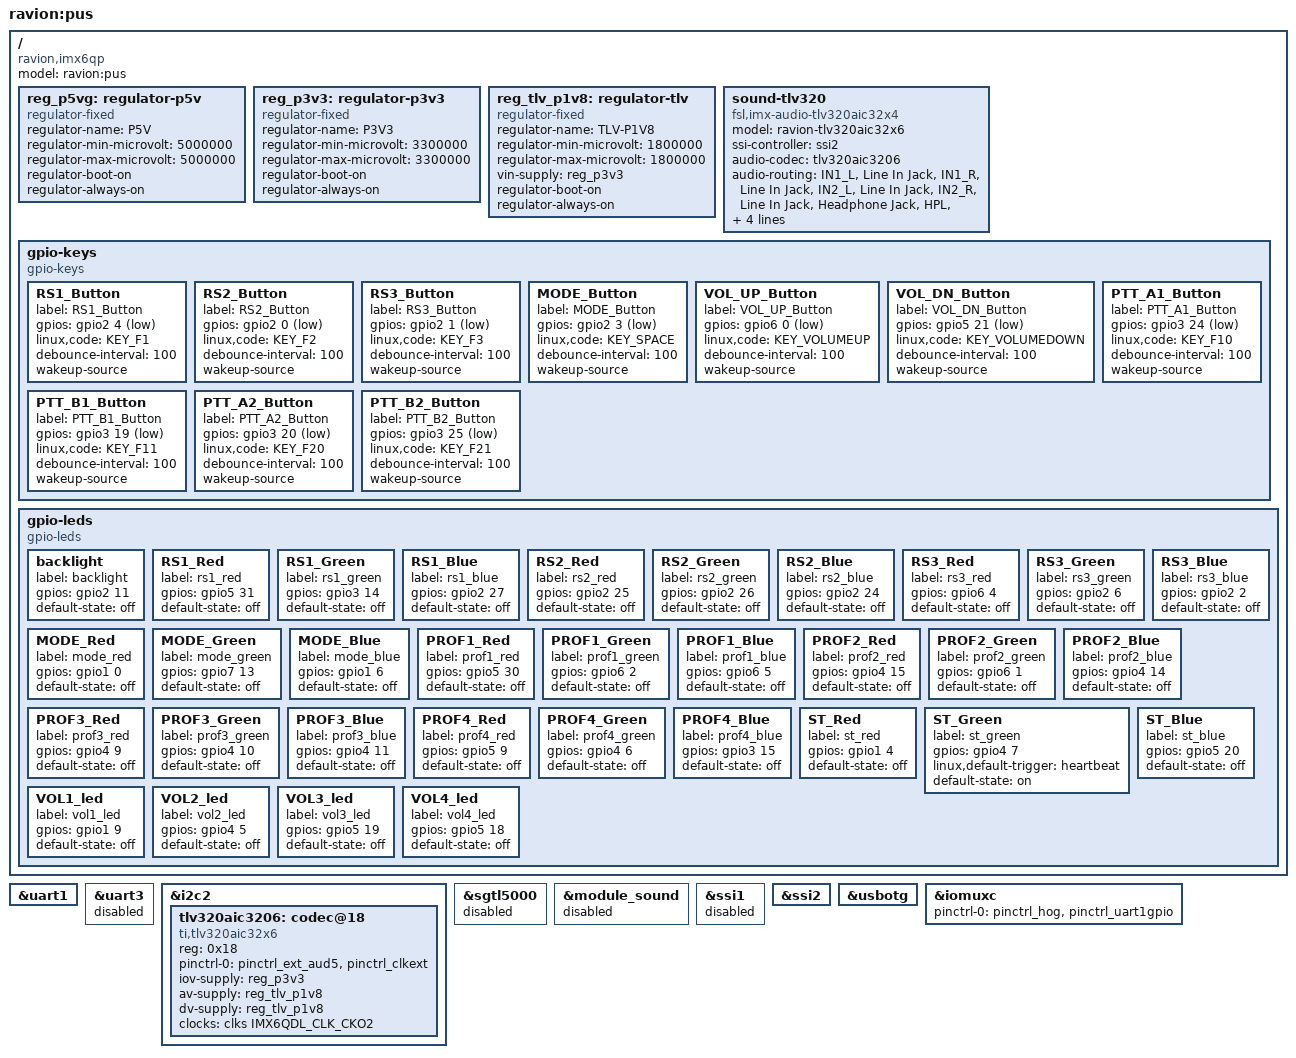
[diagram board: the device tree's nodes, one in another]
/*
 * Copyright 2025 Radioavionica Corp.
 *
 * This program is free software; you can redistribute it and/or modify
 * it under the terms of the GNU General Public License version 2 as
 * published by the Free Software Foundation.
 *
 */

/dts-v1/;
#include "imx6qp.dtsi"

#define SPI_CS_GPIO
#include "imx6qdl-ravion-v2.dtsi"

/ {
	model = "ravion:pus";
	compatible = "ravion,imx6qp", "fsl,imx6qp";

	/*
	 * Device specific regulators
	 */
	reg_p5vg: regulator-p5v { /* DA1 */
			compatible = "regulator-fixed";
			regulator-name = "P5V";
			regulator-min-microvolt = <5000000>;
			regulator-max-microvolt = <5000000>;
			regulator-boot-on;
			regulator-always-on;
	};

	reg_p3v3: regulator-p3v3 { /* DA2 */
			compatible = "regulator-fixed";
			regulator-name = "P3V3";
			regulator-min-microvolt = <3300000>;
			regulator-max-microvolt = <3300000>;
			regulator-boot-on;
			regulator-always-on;
	};

	reg_tlv_p1v8: regulator-tlv { /* DA3 */
			compatible = "regulator-fixed";
			regulator-name = "TLV-P1V8";
			regulator-min-microvolt = <1800000>;
			regulator-max-microvolt = <1800000>;
			vin-supply = <&reg_p3v3>;
			regulator-boot-on;
			regulator-always-on;
	};

	sound-tlv320 {
		compatible = "fsl,imx-audio-tlv320aic32x4";
		model = "ravion-tlv320aic32x6";
		ssi-controller = <&ssi2>;
		audio-codec = <&tlv320aic3206>;
		audio-routing =
			"IN1_L", "Line In Jack",
			"IN1_R", "Line In Jack",
			"IN2_L", "Line In Jack",
			"IN2_R", "Line In Jack",
			"Headphone Jack", "HPL",
			"Headphone Jack", "HPR",
			"Line Out Jack", "LOL",
			"Line Out Jack", "LOR";
		mux-int-port = <2>;
		mux-ext-port = <5>;
	};

	gpio-keys {
		compatible = "gpio-keys";

		RS1_Button {
			label = "RS1_Button";
			gpios = <&gpio2 4 GPIO_ACTIVE_LOW>;	/* soDimm 119 */
			linux,code = <KEY_F1>;
			debounce-interval = <100>;
			wakeup-source;
		};

		RS2_Button {
			label = "RS2_Button";
			gpios = <&gpio2 0 GPIO_ACTIVE_LOW>;	/* soDimm 111 */
			linux,code = <KEY_F2>;
			debounce-interval = <100>;
			wakeup-source;
		};

		RS3_Button {
			label = "RS3_Button";
			gpios = <&gpio2 1 GPIO_ACTIVE_LOW>;	/* soDimm 113 */
			linux,code = <KEY_F3>;
			debounce-interval = <100>;
			wakeup-source;
		};

		MODE_Button {
			label = "MODE_Button";
			gpios = <&gpio2 3 GPIO_ACTIVE_LOW>;	/* soDimm 117 */
			linux,code = <KEY_SPACE>;
			debounce-interval = <100>;
			wakeup-source;
		};

		VOL_UP_Button {
			label = "VOL_UP_Button";
			gpios = <&gpio6 0 GPIO_ACTIVE_LOW>;	/* soDimm 168 */
			linux,code = <KEY_VOLUMEUP>;
			debounce-interval = <100>;
			wakeup-source;
		};

		VOL_DN_Button {
			label = "VOL_DN_Button";
			gpios = <&gpio5 21 GPIO_ACTIVE_LOW>;	/* soDimm 170 */
			linux,code = <KEY_VOLUMEDOWN>;
			debounce-interval = <100>;
			wakeup-source;
		};

		PTT_A1_Button {
			label = "PTT_A1_Button";
			gpios = <&gpio3 24 GPIO_ACTIVE_LOW>;	/* soDimm 23 */
			linux,code = <KEY_F10>;
			debounce-interval = <100>;
			wakeup-source;
		};

		PTT_B1_Button {
			label = "PTT_B1_Button";
			gpios = <&gpio3 19 GPIO_ACTIVE_LOW>;	/* soDimm 25 */
			linux,code = <KEY_F11>;
			debounce-interval = <100>;
			wakeup-source;
		};

		PTT_A2_Button {
			label = "PTT_A2_Button";
			gpios = <&gpio3 20 GPIO_ACTIVE_LOW>;	/* soDimm 27 */
			linux,code = <KEY_F20>;
			debounce-interval = <100>;
			wakeup-source;
		};

		PTT_B2_Button {
			label = "PTT_B2_Button";
			gpios = <&gpio3 25 GPIO_ACTIVE_LOW>;	/* soDimm 29 */
			linux,code = <KEY_F21>;
			debounce-interval = <100>;
			wakeup-source;
		};
	};

	gpio-leds {
		compatible = "gpio-leds";

		backlight 	{
			label = "backlight";
			gpios = <&gpio2 11 GPIO_ACTIVE_HIGH>;		/* soDimm 133 */
			default-state = "off";
		};

		RS1_Red 	{
			label = "rs1_red";
			gpios = <&gpio5 31 GPIO_ACTIVE_HIGH>;		/* soDimm 116 */
			default-state = "off";
		};

		RS1_Green 	{
			label = "rs1_green";
			gpios = <&gpio3 14 GPIO_ACTIVE_HIGH>;		/* soDimm 118 */
			default-state = "off";
		};

		RS1_Blue 	{
			label = "rs1_blue";
			gpios = <&gpio2 27 GPIO_ACTIVE_HIGH>;		/* soDimm 114 */
			default-state = "off";
		};

		RS2_Red 	{
			label = "rs2_red";
			gpios = <&gpio2 25 GPIO_ACTIVE_HIGH>;		/* soDimm 110 */
			default-state = "off";
		};

		RS2_Green 	{
			label = "rs2_green";
			gpios = <&gpio2 26 GPIO_ACTIVE_HIGH>;		/* soDimm 112 */
			default-state = "off";
		};

		RS2_Blue 	{
			label = "rs2_blue";
			gpios = <&gpio2 24 GPIO_ACTIVE_HIGH>;		/* soDimm 106 */
			default-state = "off";
		};

		RS3_Red 	{
			label = "rs3_red";
			gpios = <&gpio6 4 GPIO_ACTIVE_HIGH>;		/* soDimm 85 */
			default-state = "off";
		};

		RS3_Green 	{
			label = "rs3_green";
			gpios = <&gpio2 6 GPIO_ACTIVE_HIGH>;		/* soDimm 123 */
			default-state = "off";
		};

		RS3_Blue 	{
			label = "rs3_blue";
			gpios = <&gpio2 2 GPIO_ACTIVE_HIGH>;		/* soDimm 115 */
			default-state = "off";
		};

		MODE_Red 	{
			label = "mode_red";
			gpios = <&gpio1 0 GPIO_ACTIVE_HIGH>;		/* soDimm 184 */
			default-state = "off";
		};

		MODE_Green 	{
			label = "mode_green";
			gpios = <&gpio7 13 GPIO_ACTIVE_HIGH>;		/* soDimm 186 */
			default-state = "off";
		};

		MODE_Blue 	{
			label = "mode_blue";
			gpios = <&gpio1 6 GPIO_ACTIVE_HIGH>;		/* soDimm 180 */
			default-state = "off";
		};

		PROF1_Red 	{
			label = "prof1_red";
			gpios = <&gpio5 30 GPIO_ACTIVE_HIGH>;		/* soDimm 164 */
			default-state = "off";
		};

		PROF1_Green 	{
			label = "prof1_green";
			gpios = <&gpio6 2 GPIO_ACTIVE_HIGH>;		/* soDimm 166 */
			default-state = "off";
		};

		PROF1_Blue 	{
			label = "prof1_blue";
			gpios = <&gpio6 5 GPIO_ACTIVE_HIGH>;		/* soDimm 162 */
			default-state = "off";
		};

		PROF2_Red 	{
			label = "prof2_red";
			gpios = <&gpio4 15 GPIO_ACTIVE_HIGH>;		/* soDimm 158 */
			default-state = "off";
		};

		PROF2_Green 	{
			label = "prof2_green";
			gpios = <&gpio6 1 GPIO_ACTIVE_HIGH>;		/* soDimm 160 */
			default-state = "off";
		};

		PROF2_Blue 	{
			label = "prof2_blue";
			gpios = <&gpio4 14 GPIO_ACTIVE_HIGH>;		/* soDimm 156 */
			default-state = "off";
		};

		PROF3_Red 	{
			label = "prof3_red";
			gpios = <&gpio4 9 GPIO_ACTIVE_HIGH>;		/* soDimm 152 */
			default-state = "off";
		};

		PROF3_Green 	{
			label = "prof3_green";
			gpios = <&gpio4 10 GPIO_ACTIVE_HIGH>;		/* soDimm 154 */
			default-state = "off";
		};

		PROF3_Blue 	{
			label = "prof3_blue";
			gpios = <&gpio4 11 GPIO_ACTIVE_HIGH>;		/* soDimm 126 */
			default-state = "off";
		};

		PROF4_Red 	{
			label = "prof4_red";
			gpios = <&gpio5 9 GPIO_ACTIVE_HIGH>;		/* soDimm 122 */
			default-state = "off";
		};

		PROF4_Green 	{
			label = "prof4_green";
			gpios = <&gpio4 6 GPIO_ACTIVE_HIGH>;		/* soDimm 124 */
			default-state = "off";
		};

		PROF4_Blue 	{
			label = "prof4_blue";
			gpios = <&gpio3 15 GPIO_ACTIVE_HIGH>;		/* soDimm 120 */
			default-state = "off";
		};

		ST_Red 	{
			label = "st_red";
			gpios = <&gpio1 4 GPIO_ACTIVE_HIGH>;		/* soDimm 188 */
			default-state = "off";
		};

		ST_Green 	{
			label = "st_green";
			gpios = <&gpio4 7 GPIO_ACTIVE_HIGH>;
			linux,default-trigger = "heartbeat";		/* soDimm 190 */
			default-state = "on";
		};

		ST_Blue 	{
			label = "st_blue";
			gpios = <&gpio5 20 GPIO_ACTIVE_HIGH>;		/* soDimm 192 */
			default-state = "off";
		};

		VOL1_led 	{
			label = "vol1_led";
			gpios = <&gpio1 9 GPIO_ACTIVE_HIGH>;		/* soDimm 178 */
			default-state = "off";
		};

		VOL2_led 	{
			label = "vol2_led";
			gpios = <&gpio4 5 GPIO_ACTIVE_HIGH>;		/* soDimm 176 */
			default-state = "off";
		};

		VOL3_led 	{
			label = "vol3_led";
			gpios = <&gpio5 19 GPIO_ACTIVE_HIGH>;		/* soDimm 174 */
			default-state = "off";
		};

		VOL4_led 	{
			label = "vol4_led";
			gpios = <&gpio5 18 GPIO_ACTIVE_HIGH>;		/* soDimm 172 */
			default-state = "off";
		};
	};
};

/*
 * Serial ports
 */
&uart1 {	status = "okay";	};
&uart3 {	status = "disabled";	};	/* routed to MAX232 but not connected */

/*
 * I2C Busses
 */
&i2c2 {	/* Compatible I2C: soDimm 194, 196 */
	status = "okay";

	/* ext codec */
	#address-cells = <1>;
	#size-cells = <0>;
	tlv320aic3206: codec@18 {
		compatible = "ti,tlv320aic32x6";
		reg = <0x18>;
		pinctrl-names = "default";
		pinctrl-0 = <&pinctrl_ext_aud5>, <&pinctrl_clkext>;
		iov-supply = <&reg_p3v3>;
		av-supply = <&reg_tlv_p1v8>;
		dv-supply = <&reg_tlv_p1v8>;
		clocks = <&clks IMX6QDL_CLK_CKO2>; /* soDimm 137 */
		clock-names = "mclk";
	};
};

/*
 * Audio (digital part)
 */
&sgtl5000 {	status = "disabled";	};
&module_sound {	status = "disabled";	};
&ssi1	{	status = "disabled";	};
&ssi2 	{	status = "okay";	}; /* for external codec */

&usbotg	{ /* OTG */
	status = "okay";
};

&iomuxc {
	pinctrl-names = "default";
	pinctrl-0 = <&pinctrl_hog>, <&pinctrl_uart1gpio>;
};

